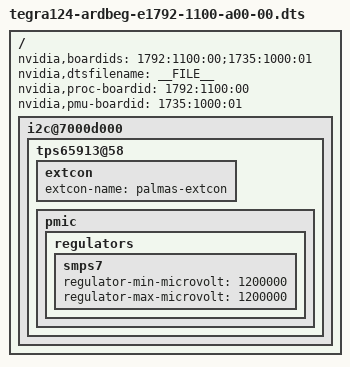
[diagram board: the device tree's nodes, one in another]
/*
 * arch/arm/boot/dts/tegra124-ardbeg-e1792-1100-a00-00.dts
 *
 * Copyright (c) 2013-2014, NVIDIA CORPORATION.  All rights reserved.
 *
 * This program is free software; you can redistribute it and/or modify
 * it under the terms of the GNU General Public License as published by
 * the Free Software Foundation; either version 2 of the License, or
 * (at your option) any later version.
 *
 * This program is distributed in the hope that it will be useful, but WITHOUT
 * ANY WARRANTY; without even the implied warranty of MERCHANTABILITY or
 * FITNESS FOR A PARTICULAR PURPOSE.  See the GNU General Public License for
 * more details.
 *
 * You should have received a copy of the GNU General Public License along
 * with this program; if not, write to the Free Software Foundation, Inc.,
 * 51 Franklin Street, Fifth Floor, Boston, MA  02110-1301, USA.
 */
/dts-v1/;

#include "tegra124-ardbeg-e1780-1000-a03-common.dtsi"
#include "tegra124-platforms/tegra124-ardbeg-power-tree-e1735-1000-a00.dtsi"
#include "tegra124-platforms/tegra124-e1780-e1735-dfll.dtsi"

/ {
	nvidia,boardids = "1792:1100:00;1735:1000:01";
	nvidia,dtsfilename = __FILE__;
	nvidia,proc-boardid = "1792:1100:00";
	nvidia,pmu-boardid = "1735:1000:01";

	i2c@7000d000 {
		tps65913@58 {
			extcon {
				 extcon-name = "palmas-extcon";
			};

			pmic {
				regulators {
					smps7 {
						regulator-min-microvolt = <1200000>;
						regulator-max-microvolt = <1200000>;
					};
				};
			};
		};
	};
};
